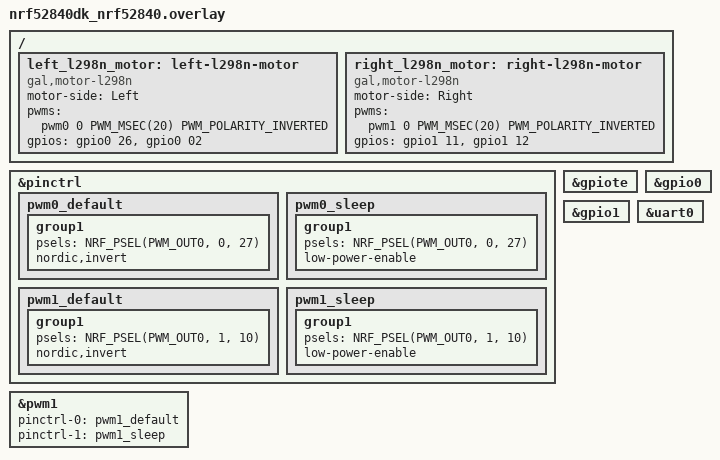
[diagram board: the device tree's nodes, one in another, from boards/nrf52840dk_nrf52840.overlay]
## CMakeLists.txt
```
#-------------------------------------------------------------------------------
# Zephyr Example Application
#
# Copyright (c) 2021 Nordic Semiconductor ASA
# SPDX-License-Identifier: Apache-2.0

cmake_minimum_required(VERSION 3.20.0)
find_package(Zephyr REQUIRED HINTS $ENV{ZEPHYR_BASE})

project(app LANGUAGES C)

target_sources(app PRIVATE src/main.c)
```

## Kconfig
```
# Copyright (c) 2021 Nordic Semiconductor ASA
# SPDX-License-Identifier: Apache-2.0
#
# This file is the application Kconfig entry point. All application Kconfig
# options can be defined here or included via other application Kconfig files.
# You can browse these options using the west targets menuconfig (terminal) or
# guiconfig (GUI).

menu "Zephyr"
source "Kconfig.zephyr"
endmenu

module = APP
module-str = app
source "subsys/logging/Kconfig.template.log_config"
```

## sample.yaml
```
# This file is provided so that the application can be compiled using Twister,
# the Zephyr testing tool. In this file, multiple combinations can be specified,
# so that you can easily test all of them locally or in CI.
sample:
  description: Example for using the l928n Motor driver
  name: Sample L928N Motor driver
common:
  sysbuild: true
  build_only: true
  integration_platforms:
    - custom_plank
tests:
  app.default: {}
  app.debug:
    extra_overlay_confs:
      - debug.conf
```

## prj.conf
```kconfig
# Copyright (c) 2021 Nordic Semiconductor ASA
# SPDX-License-Identifier: Apache-2.0
#
# This file contains selected Kconfig options for the application.

CONFIG_NCS_APPLICATION_BOOT_BANNER_STRING="Gal is building a miniT100 Tank"
CONFIG_MOTOR=y
```

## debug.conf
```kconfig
# Copyright (c) 2021 Nordic Semiconductor ASA
# SPDX-License-Identifier: Apache-2.0
#
# This is a Kconfig fragment which can be used to enable debug-related options
# in the application. See the README for more details.

# compiler
CONFIG_DEBUG_OPTIMIZATIONS=y

# logging
CONFIG_LOG=y
CONFIG_APP_LOG_LEVEL_DBG=y
CONFIG_MOTOR_LOG_LEVEL_DBG=y
```

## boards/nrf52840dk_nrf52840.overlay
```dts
/*
 * Copyright (c) 2021 Nordic Semiconductor ASA
 * SPDX-License-Identifier: Apache-2.0
 */

/ {
    left_l298n_motor: left-l298n-motor{
        compatible = "gal,motor-l298n";
        motor-side = "Left";     

        pwms = <&pwm0 0 PWM_MSEC(20) PWM_POLARITY_INVERTED>;
        // Pins order: IN3,IN4
        gpios = <&gpio0 26 GPIO_ACTIVE_HIGH>, <&gpio0 02 GPIO_ACTIVE_HIGH>;
    };
    
    right_l298n_motor: right-l298n-motor{
        compatible = "gal,motor-l298n";
        motor-side = "Right";

        pwms = <&pwm1 0 PWM_MSEC(20) PWM_POLARITY_INVERTED>;
        // Pins order: IN1,IN2
        gpios = <&gpio1 11 GPIO_ACTIVE_HIGH>, <&gpio1 12 GPIO_ACTIVE_HIGH>;
    };
    
};
&pinctrl {

	pwm0_default: pwm0_default {
		group1 {
			psels = <NRF_PSEL(PWM_OUT0, 0, 27)>;
			nordic,invert;
		};
	};

	pwm0_sleep: pwm0_sleep {
		group1 {
			psels = <NRF_PSEL(PWM_OUT0, 0, 27)>;
			low-power-enable;
		};
	};
    pwm1_default: pwm1_default {
		group1 {
			psels = <NRF_PSEL(PWM_OUT0, 1, 10)>;
			nordic,invert;
		};
	};

	pwm1_sleep: pwm1_sleep {
		group1 {
			psels = <NRF_PSEL(PWM_OUT0, 1, 10)>;
			low-power-enable;
		};
	};

};

&pwm1 {
    status = "okay";
        pinctrl-0 = <&pwm1_default>;
        pinctrl-1 = <&pwm1_sleep>;
        pinctrl-names = "default", "sleep";
};

&gpiote {
    status = "okay";
};

&gpio0 {
    status = "okay";
};
&gpio1 {
    status = "okay";
};

&uart0 {
    status = "okay";
};
```

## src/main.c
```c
/*
 * Copyright (c) 2021 Nordic Semiconductor ASA
 * SPDX-License-Identifier: Apache-2.0
 */

#include <zephyr/kernel.h>
#include <zephyr/device.h>
#include <zephyr/devicetree.h>
#include <zephyr/drivers/gpio.h>
#include <zephyr/logging/log.h>
#include <app/drivers/motor.h>
#include <zephyr/app_version.h>

LOG_MODULE_REGISTER(app, CONFIG_APP_LOG_LEVEL);

#define SW0_NODE DT_ALIAS(sw0)
static const struct gpio_dt_spec button = GPIO_DT_SPEC_GET(SW0_NODE, gpios);

#define LED0_NODE DT_ALIAS(led0)
static const struct gpio_dt_spec led = GPIO_DT_SPEC_GET(LED0_NODE, gpios);

const struct device *const left_motor = DEVICE_DT_GET(DT_NODELABEL(left_l298n_motor));
const struct device *const right_motor = DEVICE_DT_GET(DT_NODELABEL(right_l298n_motor));

static const struct device *check_l298n_motor_device(const struct device *motor)
{
	if (motor == NULL)
	{
		/* No such node, or the node does not have status "okay". */
		LOG_ERR("\nError: no device found.\n");
		return NULL;
	}

	if (!device_is_ready(motor))
	{
		LOG_ERR("\nError: Device \"%s\" is not ready; "
				"check the driver initialization logs for errors.\n",
				motor->name);
		return NULL;
	}

	LOG_INF("Found device \"%s\", getting sensor data\n", motor->name);
	return motor;
}

bool forward = true;
void button_pressed(const struct device *dev, struct gpio_callback *cb, uint32_t pins)
{
	printk("button_pressed. dev %s\n", dev->name);
	printk("dev label: %s\n", DT_PROP(LED0_NODE, label));
	gpio_pin_toggle_dt(&led);

	const struct motor_driver_api *motor_api =
		(const struct motor_driver_api *)left_motor->api;

	if (forward) // Drive Forward
	{
		motor_api->set_direction_speed(left_motor, RIGHT, 50);
		motor_api->set_direction_speed(right_motor, LEFT, 50);
		forward = false;
	}
	else // Drive Backward
	{
		forward = true;
		motor_api->set_direction_speed(left_motor, LEFT, 50);
		motor_api->set_direction_speed(right_motor, RIGHT, 50);
	}
}

static struct gpio_callback button_cb_data;

int main(void)
{
	int ret;
	printk("Version %s\n", APP_VERSION_EXTENDED_STRING);

	const struct device *ready_left_motor = check_l298n_motor_device(left_motor);
	if (ready_left_motor == NULL)
	{
		return -1;
	}

	const struct device *ready_right_motor = check_l298n_motor_device(right_motor);
	if (ready_right_motor == NULL)
	{
		return -1;
	}
	/* Only checking one since led.port and button.port point to the same device, &gpio0 */
	if (!device_is_ready(led.port))
	{
		return -1;
	}

	ret = gpio_pin_configure_dt(&led, GPIO_OUTPUT_ACTIVE);
	if (ret < 0)
	{
		return -1;
	}

	ret = gpio_pin_configure_dt(&button, GPIO_INPUT);
	if (ret < 0)
	{
		return -1;
	}

	ret = gpio_pin_interrupt_configure_dt(&button, GPIO_INT_EDGE_TO_ACTIVE);
	if (ret < 0)
	{
		return -1;
	}
	gpio_init_callback(&button_cb_data, button_pressed, BIT(button.pin));
	gpio_add_callback(button.port, &button_cb_data);

	return 0;
}
```

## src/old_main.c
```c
/*
 * Copyright (c) 2021 Nordic Semiconductor ASA
 * SPDX-License-Identifier: Apache-2.0
 */

#include <zephyr/kernel.h>
#include <zephyr/drivers/pwm.h>
#include <zephyr/drivers/gpio.h>
#include <zephyr/drivers/sensor.h>
#include <zephyr/logging/log.h>

#include <app/drivers/blink.h>

#include <app_version.h>

LOG_MODULE_REGISTER(main, CONFIG_APP_LOG_LEVEL);

#define prop DT_PROP(DT_NODELABEL(left_motor_gpio_nodelabel), gals_property)

// static const struct pwm_dt_spec motor_pwm_pin = PWM_DT_SPEC_GET(DT_NODELABEL(motor_pwm_pin));
#define MIN_PERIOD PWM_SEC(1U) / 128U
#define MAX_PERIOD PWM_SEC(1U)
#define SLEEP_DELTA_MSEC 1000U
#define NUM_STEPS 50U
#define SLEEP_MSEC 25U
#define SLEEP_SEC 1U

/* The devicetree node identifier for the "led0" alias. */
#define LED0_NODE DT_NODELABEL(motor_b_in_3)
#define LED1_NODE DT_NODELABEL(motor_b_in_4)
#define LED2_NODE DT_NODELABEL(motor_en_b)

/*
 * A build error on this line means your board is unsupported.
 * See the sample documentation for information on how to fix this.
 */
static const struct gpio_dt_spec motor_b_in_3_pin = GPIO_DT_SPEC_GET(LED0_NODE, gpios);
static const struct gpio_dt_spec motor_b_in_4_pin = GPIO_DT_SPEC_GET(LED1_NODE, gpios);
static const struct gpio_dt_spec motor_en_b_pin = GPIO_DT_SPEC_GET(LED2_NODE, gpios);

struct k_timer timer;

static void motor_direction_toggle(struct k_timer *timer)
{
	// const struct device *dev = k_timer_user_data_get(timer);
	// const struct blink_gpio_led_config *config = dev->config;
	int ret;
	LOG_DBG("timer expired");
	ret = gpio_pin_toggle_dt(&motor_b_in_3_pin);
	if (ret < 0)
	{
		LOG_ERR("Could not toggle motor_b_in_3_pin (%d)", ret);
	}
	ret = gpio_pin_toggle_dt(&motor_b_in_4_pin);
	if (ret < 0)
	{
		LOG_ERR("Could not toggle motor_b_in_4_pin (%d)", ret);
	}
}

#define BLINK_PERIOD_MS_STEP 100U
#define BLINK_PERIOD_MS_MAX 1000U
#define MOTOR_MAX_SPEED 255
int main(void)
{
	int ret;
	unsigned int period_ms = BLINK_PERIOD_MS_MAX;
	const struct device *sensor, *blink;
	struct sensor_value last_val = {0}, val;

	printk("Zephyr Example Application %s\n", APP_VERSION_STRING);
	printk("Got property: %s\n", prop);
	// if (!pwm_is_ready_dt(&motor_pwm_pin))
	// {
	// 	printk("Error: PWM device %s is not ready\n", motor_pwm_pin.dev->name);
	// 	return 0;
	// }
	uint8_t dir = 1U;
	uint32_t pulse_width = 0U;
	// uint32_t step = motor_pwm_pin.period / NUM_STEPS;

	if (!gpio_is_ready_dt(&motor_en_b_pin))
	{
		printk("Error: GPIO %s is not ready\n", motor_en_b_pin.port->name);
		return 0;
	}

	ret = gpio_pin_configure_dt(&motor_en_b_pin, GPIO_OUTPUT_HIGH);
	if (ret < 0)
	{
		return 0;
	}

	if (!gpio_is_ready_dt(&motor_b_in_3_pin))
	{
		printk("Error: GPIO %s is not ready\n", motor_b_in_3_pin.port->name);
		return 0;
	}

	ret = gpio_pin_configure_dt(&motor_b_in_3_pin, GPIO_OUTPUT_HIGH);
	if (ret < 0)
	{
		return 0;
	}

	if (!gpio_is_ready_dt(&motor_b_in_4_pin))
	{
		printk("Error: GPIO %s is not ready\n", motor_b_in_4_pin.port->name);
		return 0;
	}

	ret = gpio_pin_configure_dt(&motor_b_in_4_pin, GPIO_OUTPUT_LOW);
	if (ret < 0)
	{
		return 0;
	}

	sensor = DEVICE_DT_GET(DT_NODELABEL(example_sensor));
	if (!device_is_ready(sensor))
	{
		LOG_ERR("Sensor not ready");
		return 0;
	}

	// blink = DEVICE_DT_GET(DT_NODELABEL(blink_led));
	// if (!device_is_ready(blink)) {
	// 	LOG_ERR("Blink LED not ready");
	// 	return 0;
	// }

	// ret = blink_off(blink);
	// if (ret < 0) {
	// 	LOG_ERR("Could not turn off LED (%d)", ret);
	// 	return 0;
	// }

	// printk("Use the sensor to change LED blinking period\n");

	// while (1) {
	// 	ret = sensor_sample_fetch(sensor);
	// 	if (ret < 0) {
	// 		LOG_ERR("Could not fetch sample (%d)", ret);
	// 		return 0;
	// 	}

	// 	ret = sensor_channel_get(sensor, SENSOR_CHAN_PROX, &val);
	// 	if (ret < 0) {
	// 		LOG_ERR("Could not get sample (%d)", ret);
	// 		return 0;
	// 	}

	// 	if ((last_val.val1 == 0) && (val.val1 == 1)) {
	// 		if (period_ms == 0U) {
	// 			period_ms = BLINK_PERIOD_MS_MAX;
	// 		} else {
	// 			period_ms -= BLINK_PERIOD_MS_STEP;
	// 		}

	// 		printk("Proximity detected, setting LED period to %u ms\n",
	// 		       period_ms);
	// 		// blink_set_period_ms(blink, period_ms);
	// 	}

	// 	last_val = val;

	// 	k_sleep(K_MSEC(100));
	// }

	uint32_t period = 1000000, pulse = 1000000;
	// ret = pwm_set_dt(&motor_pwm_pin, period, pulse);
	// ret = pwm_set_pulse_dt(&motor_pwm_pin, motor_pwm_pin.period);
	// printk("Using pulse_width %d motor_pwm_pin.period %d step %d\n", pulse_width, motor_pwm_pin.period, step);
	// printk("Using pulse width %d%%\n", 100 * pulse_width / motor_pwm_pin.period);
	// while (1)
	// {
	// 	ret = pwm_set_pulse_dt(&motor_pwm_pin, pulse_width);
	// 	// ret = pwm_set_dt(&motor_pwm_pin,)
	// 	if (ret < 0)
	// 	{
	// 		printk("Error %d: failed to set pulse width\n", ret);
	// 		return 0;
	// 	}
	// 	printk("Using pulse_width %d motor_pwm_pin.period %d step %d\n", pulse_width, motor_pwm_pin.period, step);
	// 	printk("Using pulse width %d%%\n", 100 * pulse_width / motor_pwm_pin.period);
	// 	if (dir)
	// 	{
	// 		pulse_width += step;
	// 		if (pulse_width >= motor_pwm_pin.period)
	// 		{
	// 			pulse_width = motor_pwm_pin.period - step;
	// 			dir = 0U;
	// 		}
	// 	}
	// 	else
	// 	{
	// 		if (pulse_width >= step)
	// 		{
	// 			pulse_width -= step;
	// 		}
	// 		else
	// 		{
	// 			pulse_width = step;
	// 			dir = 1U;
	// 		}
	// 	}

	// 	k_sleep(K_SECONDS(SLEEP_SEC));
	// }

	k_timer_init(&timer, motor_direction_toggle, NULL);
	// k_timer_user_data_set(&data->timer, (void *)dev);

	k_timer_start(&timer, K_MSEC(500), K_MSEC(3000));
	return 0;
}
```
